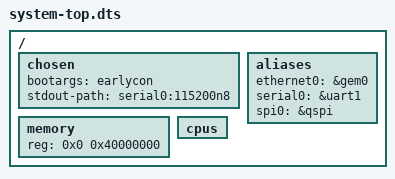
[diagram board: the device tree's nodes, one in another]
/*
 * CAUTION: This file is automatically generated by Xilinx.
 * Version:  
 * Today is: Sun Jan 28 19:30:56 2018
*/


/dts-v1/;
/include/ "zynq-7000.dtsi"
/include/ "pl.dtsi"
/include/ "pcw.dtsi"
/ {
	chosen {
		bootargs = "earlycon";
		stdout-path = "serial0:115200n8";
	};
	aliases {
		ethernet0 = &gem0;
		serial0 = &uart1;
		spi0 = &qspi;
	};
	memory {
		device_type = "memory";
		reg = <0x0 0x40000000>;
	};
	cpus {
	};
};
#include "system-user.dtsi"
